# MKW36Z4 register map
Vendor: NXP Semiconductors; Series: Kinetis_W; File version: 1.6
CPU: CM0PLUS r0p0, little endian, no MPU, no FPU, VTOR, 2 interrupt priority bits
Registers are 16-bit, read-write, no defined reset value unless marked. A register's access mark holds for its fields unless they carry their own. Offsets are from the block's base; [hi:lo] are bit positions; {n}, {i} and the like mark numbered series; 'fields as' and 'values as' point back to an identical list.

## XCVR_MISC
Base 0x4005C280
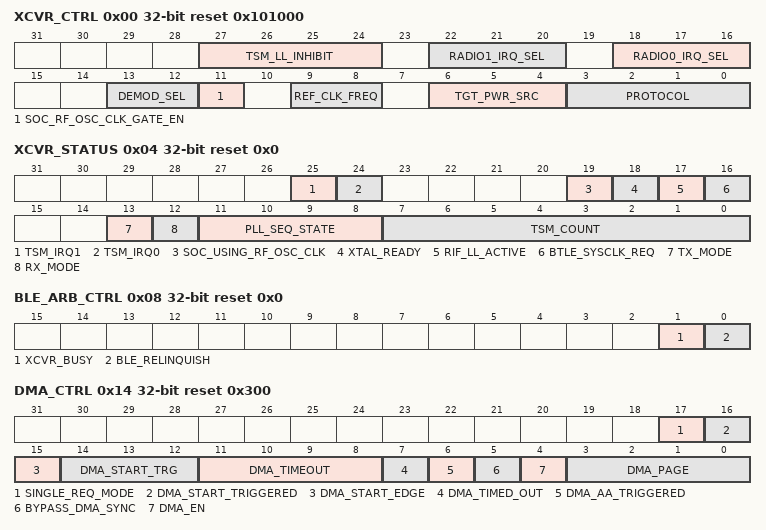
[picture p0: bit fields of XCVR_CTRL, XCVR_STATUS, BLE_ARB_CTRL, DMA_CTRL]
0x00 XCVR_CTRL 32-bit reset 0x101000 — TRANSCEIVER CONTROL
  [27:24] TSM_LL_INHIBIT — TSM Per-Link-Layer Inhibit
  [22:20] RADIO1_IRQ_SEL
    0=Assign Radio #1 Interrupt to BLE; 1=Radio #1 Interrupt unassigned; 2=Radio #1 Interrupt unassigned; 3=Assign Radio #1 Interrupt to GENERIC_FSK; {v}=Radio #1 Interrupt unassigned (v=4..7)
  [18:16] RADIO0_IRQ_SEL
    0=Assign Radio #0 Interrupt to BLE; 1=Radio #0 Interrupt unassigned; 2=Radio #0 Interrupt unassigned; 3=Assign Radio #0 Interrupt to GENERIC_FSK; {v}=Radio #0 Interrupt unassigned (v=4..7)
  [13:12] DEMOD_SEL — Demodulator Selector
    0=No demodulator selected; 1=Use NXP Multi-standard PHY demodulator
  [11] SOC_RF_OSC_CLK_GATE_EN
  [9:8] REF_CLK_FREQ — Radio Reference Clock Frequency
    0=32 MHz; 1=26 MHz
  [6:4] TGT_PWR_SRC — Target Power Source
  [3:0] PROTOCOL — Radio Protocol Selection
    0=BLE; 1=BLE in MBAN; 2=BLE overlap MBAN; 6=Radio Channels 0-127 selectable, FSK; 7=Radio Channels 0-127 selectable, GFSK; 8=Generic GFSK, with Gaussian Filter; 9=Generic MSK, O-QPSK encoding; 10=Generic FSK, direct +/- Fdev FSK
0x04 XCVR_STATUS 32-bit reset 0x0 (reset mask 0xFFF0C000) — TRANSCEIVER STATUS
  [25] TSM_IRQ1 — TSM Interrupt #1
    0=TSM Interrupt #1 is not asserted; 1=TSM Interrupt #1 is asserted. Write '1' to this bit to clear it.
  [24] TSM_IRQ0 — TSM Interrupt #0
    0=TSM Interrupt #0 is not asserted; 1=TSM Interrupt #0 is asserted. Write '1' to this bit to clear it.
  [19] SOC_USING_RF_OSC_CLK ro — SOC Using RF Clock Indication
  [18] XTAL_READY ro — RF Osciallator Xtal Ready
    0=Indicates that the RF Oscillator is disabled or has not completed its warmup; 1=Indicates that the RF Oscillator has completed its warmup count and is ready for use
  [17] RIF_LL_ACTIVE ro — Link Layer Active Indication
  [16] BTLE_SYSCLK_REQ ro — BTLE System Clock Request
  [13] TX_MODE ro — Transmit Mode
  [12] RX_MODE ro — Receive Mode
  [11:8] PLL_SEQ_STATE ro — PLL Sequence State
    0=PLL OFF; 2=CTUNE; 3=CTUNE_SETTLE; 6=HPMCAL1; 8=HPMCAL1_SETTLE; 10=HPMCAL2; 12=HPMCAL2_SETTLE; 15=PLLREADY
  [7:0] TSM_COUNT ro
0x08 BLE_ARB_CTRL 32-bit reset 0x0 — BLE ARBITRATION CONTROL
  [1] XCVR_BUSY ro — Transceiver Busy Status Bit
    0=RF Channel in available (TSM is idle); 1=RF Channel in use (TSM is busy)
  [0] BLE_RELINQUISH — BLE Relinquish Control
0x0C OVERWRITE_VER 32-bit reset 0x0 — OVERWRITE VERSION
  [7:0] OVERWRITE_VER — Overwrite Version Number.
0x14 DMA_CTRL 32-bit reset 0x300 — TRANSCEIVER DMA CONTROL
  [17] SINGLE_REQ_MODE — DMA Single Request Mode
    0=Disable Single Request Mode. The transceiver will assert ipd_req_radio_rx whenever it has a new sample ready for transfer.; 1=Enable Single Request Mode. A single initial request by the transceiver will transfer the entire DMA block of data
  [16] DMA_START_TRIGGERED ro — DMA Start Trigger Occurred
  [15] DMA_START_EDGE — DMA Start Trigger Edge Selector
    0=Trigger fires on a rising edge of the selected trigger source; 1=Trigger fires on a falling edge of the selected trigger source
  [14:12] DMA_START_TRG — DMA Start Trigger Selector
  [11:8] DMA_TIMEOUT
  [7] DMA_TIMED_OUT — DMA Transfer Timed Out
    0=A DMA timeout has not occurred; 1=A DMA timeout has occurred in Single Request Mode since the last time this bit was cleared
  [6] DMA_AA_TRIGGERED ro — DMA Access Address triggered
  [5] BYPASS_DMA_SYNC — Bypass External DMA Synchronization
    0=Don't Bypass External Synchronization. Use this setting if SINGLE_REQ_MODE=1.; 1=Bypass External Synchronization. This setting is mandatory if SINGLE_REQ_MODE=0.
  [4] DMA_EN — DMA Enable
  [3:0] DMA_PAGE — Transceiver DMA Page Selector
    0=DMA Idle; 1=RX_DIG I and Q; 2=RX_DIG I Only; 3=RX_DIG Q Only; 4=RAW ADC I and Q; 5=RAW ADC I Only; 6=RAW ADC Q only; 7=DC Estimator I and Q; 8=DC Estimator I Only; 9=DC Estimator Q only; 10=RX_DIG Phase Output; 12=Demodulator Soft Decision; 13=Demodulator Data Output; 14=Demodulator CFO Phase Output
0x18 DMA_DATA 32-bit ro reset 0x0 — TRANSCEIVER DMA DATA
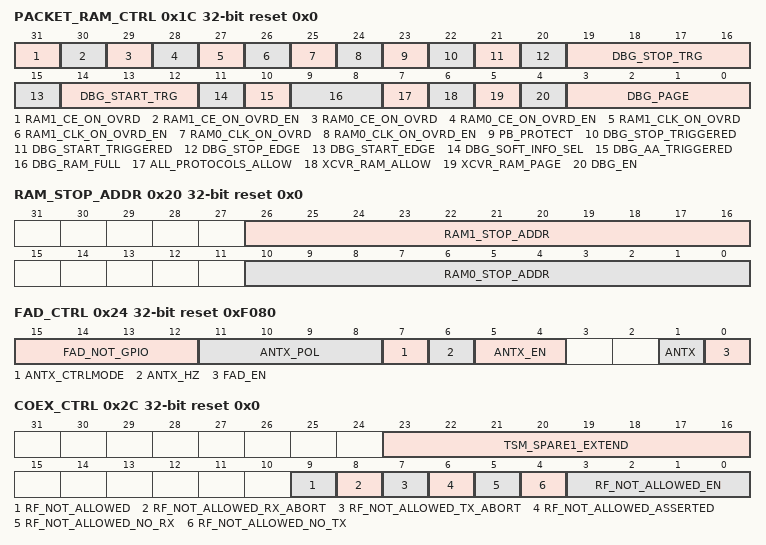
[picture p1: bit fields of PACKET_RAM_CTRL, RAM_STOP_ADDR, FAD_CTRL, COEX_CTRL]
0x1C PACKET_RAM_CTRL 32-bit reset 0x0 — PACKET RAM CONTROL
  [31] RAM1_CE_ON_OVRD — Override value for RAM1 CE (Chip Enable)
  [30] RAM1_CE_ON_OVRD_EN — Override control for RAM1 CE (Chip Enable)
    0=Normal operation; 1=Use the state of RAM1_CE_ON_OVRD to override the RAM1 CE
  [29] RAM0_CE_ON_OVRD — Override value for RAM0 CE (Chip Enable)
  [28] RAM0_CE_ON_OVRD_EN — Override control for RAM0 CE (Chip Enable)
    0=Normal operation; 1=Use the state of RAM0_CE_ON_OVRD to override the RAM0 CE
  [27] RAM1_CLK_ON_OVRD — Override value for RAM1 Clock Gate Enable
  [26] RAM1_CLK_ON_OVRD_EN — Override control for RAM1 Clock Gate Enable
    0=Normal operation; 1=Use the state of RAM1_CLK_ON_OVRD to override the RAM1 Clock Gate Enable
  [25] RAM0_CLK_ON_OVRD — Override value for RAM0 Clock Gate Enable
  [24] RAM0_CLK_ON_OVRD_EN — Override control for RAM0 Clock Gate Enable
    0=Normal operation; 1=Use the state of RAM0_CLK_ON_OVRD to override the RAM0 Clock Gate Enable
  [23] PB_PROTECT — Packet Buffer Protect
    0=Incoming received packets overwrite Packet Buffer RX contents (default); 1=Incoming received packets are blocked from overwriting Packet Buffer RX contents
  [22] DBG_STOP_TRIGGERED ro — Packet RAM Debug Stop Triggered
  [21] DBG_START_TRIGGERED ro — Packet RAM Debug Start Triggered
  [20] DBG_STOP_EDGE — Packet RAM Debug Stop Trigger Edge Selector
    values as DMA_CTRL.DMA_START_EDGE
  [19:16] DBG_STOP_TRG — Packet RAM Debug Stop Trigger Selector
  [15] DBG_START_EDGE — Packet RAM Debug Start Trigger Edge Selector
    values as DMA_CTRL.DMA_START_EDGE
  [14:12] DBG_START_TRG — Packet RAM Debug Start Trigger Selector
  [11] DBG_SOFT_INFO_SEL — Packet RAM Debug PHY Soft Info Output Selector
    0=PHY input cg_vbr_en is used to capture soft decision data; 1=PHY output fsk_demod_bit_valid is used to capture soft decision data
  [10] DBG_AA_TRIGGERED ro — Packet Ram Debug Access Address triggered
  [9:8] DBG_RAM_FULL ro — DBG_RAM_FULL[1:0]
    0=Neither Packet RAM0 nor RAM1 is full
  [7] ALL_PROTOCOLS_ALLOW — Allow IPS bus access to Packet RAM for any protocol at any time.
    0=IPS bus access to Packet RAM is restricted to the protocol engine currently selected by XCVR_CTRL[PROTOCOL]; 1=All IPS bus access to Packet RAM permitted, regardless of XCVR_CTRL[PROTOCOL] setting
  [6] XCVR_RAM_ALLOW — Allow Packet RAM Transceiver Access
    0=Protocol Engines, and associated IPS busses, have exclusive access to Packet RAM (mission mode); 1=Transceiver-space access to Packet RAM, including Packet RAM debug mode, are allowed
  [5] XCVR_RAM_PAGE — RAM Page Selector for XCVR Access
    0=RAM0 is mapped into XCVR address space, between XCVR_BASE + 0x700, and XCVR_BASE + 0xFFF; 1=RAM1 is mapped into XCVR address space, between XCVR_BASE + 0x700, and XCVR_BASE + 0xFFF
  [4] DBG_EN — Packet RAM Debug Mode Enable
  [3:0] DBG_PAGE — Packet RAM Debug Page Selector
    0=Packet RAM Debug Mode Idle; 1=RX_DIG I and Q; 4=RAW ADC I and Q; 7=DC Estimator I and Q; 10=RX_DIG Phase Output; 12=Demodulator Soft Decision; 13=Demodulator Data Output; 14=Demodulator CFO Phase Output
0x20 RAM_STOP_ADDR 32-bit ro reset 0x0 — PACKET RAM DEBUG RAM STOP ADDRESS
  [26:16] RAM1_STOP_ADDR — RAM1 Stop Address
  [10:0] RAM0_STOP_ADDR — RAM0 Stop Address
0x24 FAD_CTRL 32-bit reset 0xF080 — FAD CONTROL
  [15:12] FAD_NOT_GPIO — FAD versus GPIO Mode Selector
  [11:8] ANTX_POL — FAD Antenna Controls Polarity
  [7] ANTX_CTRLMODE — Antenna Diversity Control Mode
  [6] ANTX_HZ — This bit currently has no functionality
  [5:4] ANTX_EN — These bits currently have no functionality
  [1] ANTX — This bit currently has no functionality
  [0] FAD_EN — This bit currently has no functionality
0x2C COEX_CTRL 32-bit reset 0x0 — COEXISTENCE CONTROL
  [23:16] TSM_SPARE1_EXTEND — TSM_SPARE1_EX Extension Duration
  [9] RF_NOT_ALLOWED ro
  [8] RF_NOT_ALLOWED_RX_ABORT
    0=A RX abort due to assertion on RF_NOT_ALLOWED has not occurred; 1=A RX abort due to assertion on RF_NOT_ALLOWED has occurred since the last time this bit was cleared
  [7] RF_NOT_ALLOWED_TX_ABORT
    0=A TX abort due to assertion on RF_NOT_ALLOWED has not occurred; 1=A TX abort due to assertion on RF_NOT_ALLOWED has occurred since the last time this bit was cleared
  [6] RF_NOT_ALLOWED_ASSERTED
    0=Assertion on RF_NOT_ALLOWED has not occurred; 1=Assertion on RF_NOT_ALLOWED has occurred since the last time this bit was cleared
  [5] RF_NOT_ALLOWED_NO_RX
    0=Assertion on RF_NOT_ALLOWED has no effect on RX; 1=Assertion on RF_NOT_ALLOWED can abort RX
  [4] RF_NOT_ALLOWED_NO_TX
    0=Assertion on RF_NOT_ALLOWED has no effect on TX; 1=Assertion on RF_NOT_ALLOWED can abort TX
  [3:0] RF_NOT_ALLOWED_EN — RF_NOT_ALLOWED PER-LINK-LAYER ENABLE
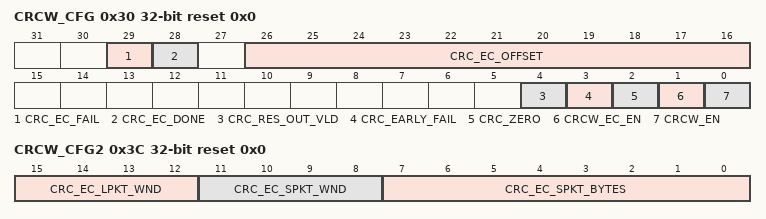
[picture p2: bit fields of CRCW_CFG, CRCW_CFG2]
0x30 CRCW_CFG 32-bit reset 0x0 — CRC/WHITENER CONFIG REGISTER
  [29] CRC_EC_FAIL ro — CRC error correction fail
  [28] CRC_EC_DONE ro — CRC error correction done
  [26:16] CRC_EC_OFFSET ro — CRC error correction offset
  [4] CRC_RES_OUT_VLD ro — CRC result output valid
  [3] CRC_EARLY_FAIL ro — CRC error correction fail
  [2] CRC_ZERO ro
  [1] CRCW_EC_EN — CRC Error Correction Enable
  [0] CRCW_EN — CRC calculation enable
0x34 CRC_EC_MASK 32-bit ro reset 0x0 — CRC ERROR CORRECTION MASK
  [31:0] CRC_EC_MASK — CRC error correction mask
0x38 CRC_RES_OUT 32-bit ro reset 0x0 — CRC RESULT
  [31:0] CRC_RES_OUT — CRC result output
0x3C CRCW_CFG2 32-bit reset 0x0 — CRC/WHITENER CONFIG 2 REGISTER
  [15:12] CRC_EC_LPKT_WND — Error correction long packet burst error window
  [11:8] CRC_EC_SPKT_WND — Error correction short packet burst error window
  [7:0] CRC_EC_SPKT_BYTES — Error Correction Short Packet Bytes
